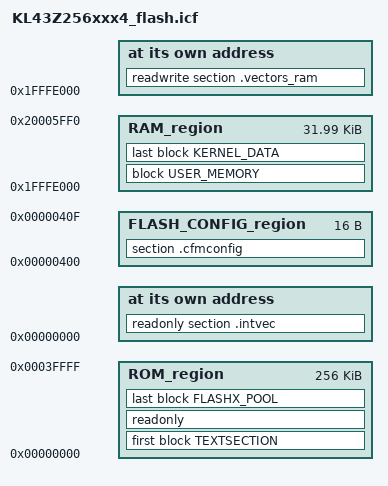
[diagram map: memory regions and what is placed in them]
/*###ICF### Section handled by ICF editor, don't touch! ****/
/*-Editor annotation file-*/
/* IcfEditorFile="$TOOLKIT_DIR$\config\ide\IcfEditor\cortex_v1_0.xml" */
/*-Specials-*/
define symbol __ICFEDIT_intvec_start__ = 0x00000000;
/*-Memory Regions-*/
define symbol __ICFEDIT_region_ROM_start__   = 0x00000000 ;
define symbol __ICFEDIT_region_ROM_end__     = 0x0003FFFF;
define symbol __ICFEDIT_region_RAM_start__   = 0x1FFFE000;
define symbol __ICFEDIT_region_RAM_end__     = 0x20005FF0;
/*-Sizes-*/
define symbol __ICFEDIT_size_cstack__   = 0x00;
define symbol __ICFEDIT_size_heap__     = 0;
/**** End of ICF editor section. ###ICF###*/

define exported symbol __INTERNAL_FLASH_BASE    = 0x00000000;
define exported symbol __INTERNAL_FLASH_SIZE    = 0x00040000;
define exported symbol __INTERNAL_SRAM_BASE     = 0x1FFFE000;
define exported symbol __INTERNAL_SRAM_SIZE     = 0x00008000;
define exported symbol __SRAM_POOL              = 0x1FFFE000;

define exported symbol __INTERNAL_FLEXNVM_BASE = 0;
define exported symbol __INTERNAL_FLEXNVM_SIZE = 0;

define exported symbol __VECTOR_TABLE_ROM_START = 0x00000000;
define exported symbol __VECTOR_TABLE_RAM_START = __ICFEDIT_region_RAM_start__;

define exported symbol __DEFAULT_PROCESSOR_NUMBER = 1;
define exported symbol __DEFAULT_INTERRUPT_STACK_SIZE = 512;

/* mem_init writes a storeblock_struct at the end of kernel data, max size 32 bytes, so use 0x100 offset */
define exported symbol __BOOT_STACK_ADDRESS = __ICFEDIT_region_RAM_end__ - 0x100;

define exported symbol __KERNEL_AREA_START = __ICFEDIT_region_RAM_start__;
define exported symbol __KERNEL_AREA_END = 0x20005FF0;
define exported symbol __USER_AREA_START = 0x20006000;
define exported symbol __USER_AREA_END = __ICFEDIT_region_RAM_end__;

define exported symbol __KERNEL_DATA_END = __ICFEDIT_region_RAM_end__;

define memory mem with size = 4G;
define region ROM_region   = mem:[from __ICFEDIT_region_ROM_start__   to __ICFEDIT_region_ROM_end__];
define region RAM_region   = mem:[from __ICFEDIT_region_RAM_start__   to __ICFEDIT_region_RAM_end__];

define block KERNEL_DATA with alignment = 8 { section .kernel_data };

define block USER_NO_MEMORY with alignment = 32 { section .nouser };
define block USER_RO_MEMORY with alignment = 32 { section .rouser };
define block USER_RW_MEMORY with alignment = 32 { section .rwuser };
define block USER_DEFAULT_MEMORY with alignment = 32 { readwrite };

// define block with fixed order - we need fixed order for simplest  MPU settings
define block USER_MEMORY with fixed order, alignment = 32 { block USER_NO_MEMORY, block USER_RO_MEMORY, block USER_RW_MEMORY, block USER_DEFAULT_MEMORY };

define exported symbol __FLASHX_SECT_SIZE = 0x0400;
define exported symbol __FLASHX_END_ADDR  = __INTERNAL_FLASH_BASE + __INTERNAL_FLASH_SIZE;

define symbol __FLASH_CONFIG_START        = 0x00000400;
define symbol __FLASH_CONFIG_END          = 0x0000040F;
define region FLASH_CONFIG_region         = mem:[from __FLASH_CONFIG_START to __FLASH_CONFIG_END];
place in FLASH_CONFIG_region              { section .cfmconfig };

define block FLASHX_POOL with alignment = __FLASHX_SECT_SIZE { section .flashx };
define block TEXTSECTION with alignment = 4 { section .text };
keep { section .cfmconfig };
keep { section .flashx };

initialize by copy { readwrite };
do not initialize  { section .noinit };
do not initialize  { section .kernel_data };
do not initialize  { section .flashx };

place at address mem:__ICFEDIT_intvec_start__ { readonly section .intvec};
place in ROM_region { first block TEXTSECTION, readonly,  last block FLASHX_POOL };

place at address mem:__ICFEDIT_region_RAM_start__ { readwrite section .vectors_ram };

/* each block/segment must be in one line (association to region) because I need kernel data start after other datas */
place in RAM_region   { block USER_MEMORY, last block KERNEL_DATA };

